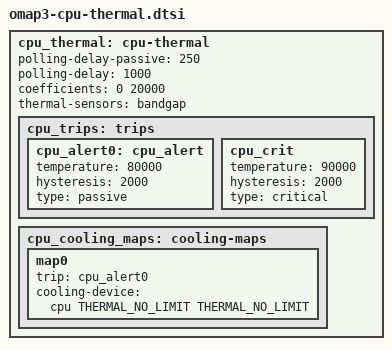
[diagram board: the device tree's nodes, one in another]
// SPDX-License-Identifier: GPL-2.0-only
/*
 * Device Tree Source for OMAP3 SoC CPU thermal
 *
 * Copyright (C) 2017 Texas Instruments Incorporated - https://www.ti.com/
 */

#include <dt-bindings/thermal/thermal.h>

cpu_thermal: cpu-thermal {
	polling-delay-passive = <250>; /* milliseconds */
	polling-delay = <1000>; /* milliseconds */
	coefficients = <0 20000>;

	thermal-sensors = <&bandgap>;

	cpu_trips: trips {
		cpu_alert0: cpu_alert {
			temperature = <80000>; /* millicelsius */
			hysteresis = <2000>; /* millicelsius */
			type = "passive";
		};
		cpu_crit: cpu_crit {
			temperature = <90000>; /* millicelsius */
			hysteresis = <2000>; /* millicelsius */
			type = "critical";
		};
	};

	cpu_cooling_maps: cooling-maps {
		map0 {
			trip = <&cpu_alert0>;
			cooling-device =
				<&cpu THERMAL_NO_LIMIT THERMAL_NO_LIMIT>;
		};
	};
};
